VERSION ""

NS_ :

BS_:

BU_:

BO_ 272 gnss_LatLon: 8 Vector__XXX
 SG_ lat : 0|32@1- (1e-07,0) [-90|90] "deg" Vector__XXX
 SG_ lon : 32|32@1- (1e-07,0) [-180|180] "deg" Vector__XXX

BO_ 273 gnss_HeadHeight: 8 Vector__XXX
 SG_ heading : 0|32@1- (1e-05,0) [0|360] "deg" Vector__XXX
 SG_ height : 32|32@1- (0.001,0) [0|0] "m" Vector__XXX

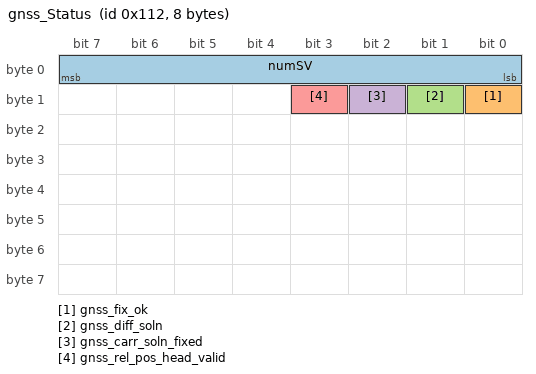
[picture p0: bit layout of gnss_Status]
BO_ 274 gnss_Status: 8 Vector__XXX
 SG_ numSV : 0|8@1+ (1,0) [0|31] "" Vector__XXX
 SG_ gnss_fix_ok : 8|1@1+ (1,0) [0|0] "" Vector__XXX
 SG_ gnss_diff_soln : 9|1@1+ (1,0) [0|0] "" Vector__XXX
 SG_ gnss_carr_soln_fixed : 10|1@1+ (1,0) [0|0] "" Vector__XXX
 SG_ gnss_rel_pos_head_valid : 11|1@1+ (1,0) [0|0] "" Vector__XXX

SIG_VALTYPE_ 272 lat : 1;
SIG_VALTYPE_ 272 lon : 1;
SIG_VALTYPE_ 273 heading : 1;
SIG_VALTYPE_ 273 height : 1;
